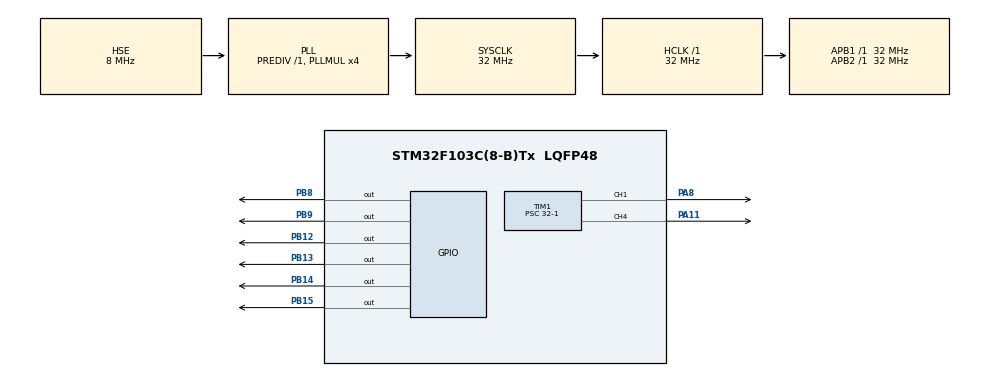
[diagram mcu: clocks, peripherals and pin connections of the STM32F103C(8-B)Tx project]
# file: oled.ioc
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Mcu.Family=STM32F1
Mcu.Name=STM32F103C(8-B)Tx
Mcu.Package=LQFP48
NVIC.PriorityGroup=NVIC_PRIORITYGROUP_4
PA11.Signal=S_TIM1_CH4
PA13.Mode=Serial_Wire
PA13.Signal=SYS_JTMS-SWDIO
PA14.Mode=Serial_Wire
PA14.Signal=SYS_JTCK-SWCLK
PA8.Signal=S_TIM1_CH1
PB12.Signal=GPIO_Output
PB13.Signal=GPIO_Output
PB14.Signal=GPIO_Output
PB15.Signal=GPIO_Output
PB8.GPIO_ModeDefaultOutputPP=GPIO_MODE_OUTPUT_PP
PB8.GPIO_PuPd=GPIO_NOPULL
PB8.GPIO_Speed=GPIO_SPEED_FREQ_LOW
PB8.PinState=GPIO_PIN_RESET
PB8.Signal=GPIO_Output
PB9.GPIO_ModeDefaultOutputPP=GPIO_MODE_OUTPUT_PP
PB9.GPIO_PuPd=GPIO_NOPULL
PB9.GPIO_Speed=GPIO_SPEED_FREQ_LOW
PB9.PinState=GPIO_PIN_RESET
PB9.Signal=GPIO_Output
PC14-OSC32_IN.Mode=LSE-External-Oscillator
PC14-OSC32_IN.Signal=RCC_OSC32_IN
PC15-OSC32_OUT.Mode=LSE-External-Oscillator
PC15-OSC32_OUT.Signal=RCC_OSC32_OUT
PD0-OSC_IN.Mode=HSE-External-Oscillator
PD0-OSC_IN.Signal=RCC_OSC_IN
PD1-OSC_OUT.Mode=HSE-External-Oscillator
PD1-OSC_OUT.Signal=RCC_OSC_OUT
ProjectManager.HeapSize=0x200
ProjectManager.StackSize=0x400
ProjectManager.TargetToolchain=MDK-ARM V5.27
RCC.AHBFreq_Value=32000000
RCC.APB1Freq_Value=32000000
RCC.APB1TimFreq_Value=32000000
RCC.APB2Freq_Value=32000000
RCC.APB2TimFreq_Value=32000000
RCC.HCLKFreq_Value=32000000
RCC.PLLMUL=RCC_PLL_MUL4
RCC.PLLSourceVirtual=RCC_PLLSOURCE_HSE
RCC.SYSCLKFreq_VALUE=32000000
RCC.SYSCLKSource=RCC_SYSCLKSOURCE_PLLCLK
RCC.USBFreq_Value=32000000
SH.S_TIM1_CH1.0=TIM1_CH1,PWM Generation1 CH1
SH.S_TIM1_CH4.0=TIM1_CH4,PWM Generation4 CH4
TIM1.Channel-PWM\ Generation1\ CH1=TIM_CHANNEL_1
TIM1.Channel-PWM\ Generation4\ CH4=TIM_CHANNEL_4
TIM1.Period=1000-1
TIM1.Prescaler=32-1
VP_TIM1_VS_ClockSourceINT.Mode=Internal
board=custom

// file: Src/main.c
/* USER CODE BEGIN Header */
/**
  ******************************************************************************
  * @file           : main.c
  * @brief          : Main program body
  ******************************************************************************
  * @attention
  *
  * <h2><center>&copy; Copyright (c) 2024 STMicroelectronics.
  * All rights reserved.</center></h2>
  *
  * This software component is licensed by ST under BSD 3-Clause license,
  * the "License"; You may not use this file except in compliance with the
  * License. You may obtain a copy of the License at:
  *                        opensource.org/licenses/BSD-3-Clause
  *
  ******************************************************************************
  */
/* USER CODE END Header */

#include "main.h"
#include "tim.h"
#include "gpio.h"

/* USER CODE BEGIN Includes */
#include "oled.h"
/* USER CODE END Includes */

/* USER CODE BEGIN PM */
#define size 16
/* USER CODE END PM */

void SystemClock_Config(void);

int main(void)
{

  /* MCU Configuration--------------------------------------------------------*/

  /* Reset of all peripherals, Initializes the Flash interface and the Systick. */
  HAL_Init();

  /* Configure the system clock */
  SystemClock_Config();

  /* Initialize all configured peripherals */
  MX_GPIO_Init();
  MX_TIM1_Init();
  /* USER CODE BEGIN 2 */
  OLED_Init();
  OLED_Clear();

  /* USER CODE END 2 */

  /* Infinite loop */
  /* USER CODE BEGIN WHILE */
  while (1)
  {

   OLED_ShowChar(6,1,'a',size);

    /* USER CODE END WHILE */

  }
}

void SystemClock_Config(void)
{
  RCC_OscInitTypeDef RCC_OscInitStruct = {0};
  RCC_ClkInitTypeDef RCC_ClkInitStruct = {0};

  /** Initializes the CPU, AHB and APB busses clocks
  */
  RCC_OscInitStruct.OscillatorType = RCC_OSCILLATORTYPE_HSE;
  RCC_OscInitStruct.HSEState = RCC_HSE_ON;
  RCC_OscInitStruct.HSEPredivValue = RCC_HSE_PREDIV_DIV1;
  RCC_OscInitStruct.HSIState = RCC_HSI_ON;
  RCC_OscInitStruct.PLL.PLLState = RCC_PLL_ON;
  RCC_OscInitStruct.PLL.PLLSource = RCC_PLLSOURCE_HSE;
  RCC_OscInitStruct.PLL.PLLMUL = RCC_PLL_MUL4;
  if (HAL_RCC_OscConfig(&RCC_OscInitStruct) != HAL_OK)
  {
    Error_Handler();
  }
  /** Initializes the CPU, AHB and APB busses clocks
  */
  RCC_ClkInitStruct.ClockType = RCC_CLOCKTYPE_HCLK|RCC_CLOCKTYPE_SYSCLK
                              |RCC_CLOCKTYPE_PCLK1|RCC_CLOCKTYPE_PCLK2;
  RCC_ClkInitStruct.SYSCLKSource = RCC_SYSCLKSOURCE_PLLCLK;
  RCC_ClkInitStruct.AHBCLKDivider = RCC_SYSCLK_DIV1;
  RCC_ClkInitStruct.APB1CLKDivider = RCC_HCLK_DIV1;
  RCC_ClkInitStruct.APB2CLKDivider = RCC_HCLK_DIV1;

  if (HAL_RCC_ClockConfig(&RCC_ClkInitStruct, FLASH_LATENCY_1) != HAL_OK)
  {
    Error_Handler();
  }
}

void Error_Handler(void)
{
}

/************************ (C) COPYRIGHT STMicroelectronics *****END OF FILE****/
